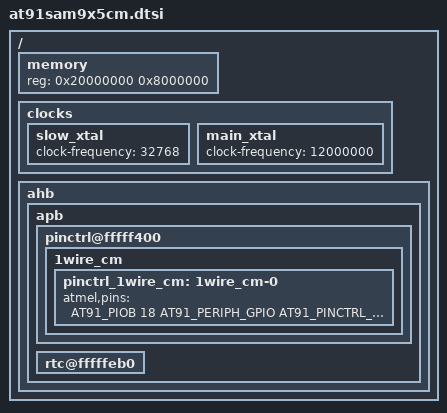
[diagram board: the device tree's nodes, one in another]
/*
 * at91sam9x5cm.dtsi - Device Tree Include file for AT91SAM9x5 CPU Module
 *
 *  Copyright (C) 2012 Atmel,
 *                2012 Nicolas Ferre <nicolas.ferre@atmel.com>
 *
 * Licensed under GPLv2 or later.
 */

/ {
	memory {
		reg = <0x20000000 0x8000000>;
	};

	clocks {
		slow_xtal {
			clock-frequency = <32768>;
		};

		main_xtal {
			clock-frequency = <12000000>;
		};
	};

	ahb {
		apb {
			pinctrl@fffff400 {
				1wire_cm {
					pinctrl_1wire_cm: 1wire_cm-0 {
						atmel,pins = <AT91_PIOB 18 AT91_PERIPH_GPIO AT91_PINCTRL_MULTI_DRIVE>; /* PB18 multidrive, conflicts with led */
					};
				};
			};

			rtc@fffffeb0 {
				status = "okay";
			};
		};
	};

 };
